# EFR32FG1V131F256GM48 register map
File version: 3.0.0
CPU: CM4 r0p1, little endian, MPU, FPU, 3 interrupt priority bits
Registers are 32-bit, read-write, reset 0x0 unless marked. A register's access mark holds for its fields unless they carry their own. Offsets are from the block's base; [hi:lo] are bit positions; {n}, {i} and the like mark numbered series; 'fields as' and 'values as' point back to an identical list.

## CRC — RF CRC engine
Base 0x40082000
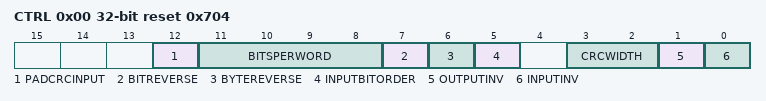
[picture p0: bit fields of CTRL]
0x00 CTRL reset 0x704
  [12] PADCRCINPUT, [11:8] BITSPERWORD, [7] BITREVERSE, [6] BYTEREVERSE, [5] INPUTBITORDER, [3:2] CRCWIDTH, [1] OUTPUTINV, [0] INPUTINV
0x04 STATUS ro
  [0] BUSY
0x08 CMD wo (reset mask 0x1)
  [5:0] INITIALIZE
0x0C INPUTDATA
  [15:0] INPUTDATA
0x10 INIT
0x14 DATA ro
0x18 POLY

## SYNTH — Frequency synthezicer
Base 0x40083000
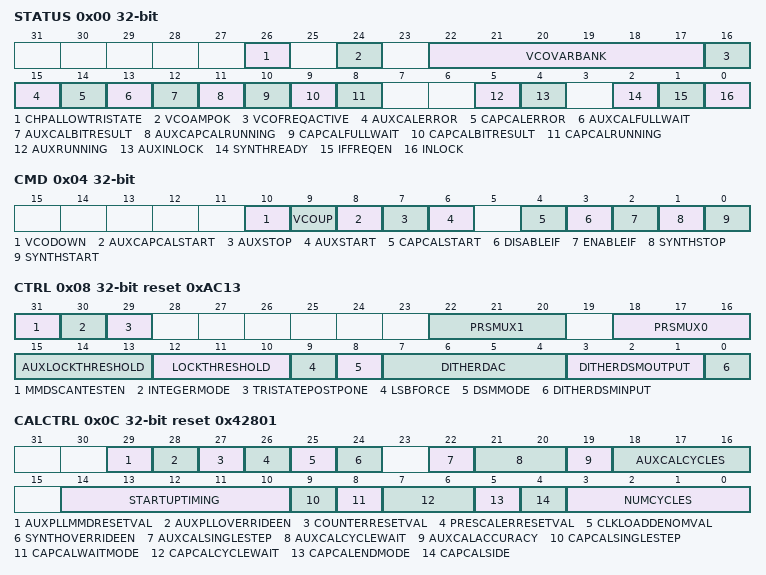
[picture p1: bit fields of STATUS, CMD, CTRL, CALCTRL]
0x00 STATUS ro
  [26] CHPALLOWTRISTATE, [24] VCOAMPOK, [22:17] VCOVARBANK, [16] VCOFREQACTIVE, [15] AUXCALERROR, [14] CAPCALERROR, [13] AUXCALFULLWAIT, [12] AUXCALBITRESULT, [11] AUXCAPCALRUNNING, [10] CAPCALFULLWAIT, [9] CAPCALBITRESULT, [8] CAPCALRUNNING, [5] AUXRUNNING, [4] AUXINLOCK, [2] SYNTHREADY, [1] IFFREQEN, [0] INLOCK
0x04 CMD wo
  [10] VCODOWN, [9] VCOUP, [8] AUXCAPCALSTART, [7] AUXSTOP, [6] AUXSTART, [4] CAPCALSTART, [3] DISABLEIF, [2] ENABLEIF, [1] SYNTHSTOP, [0] SYNTHSTART
0x08 CTRL reset 0xAC13
  [31] MMDSCANTESTEN, [30] INTEGERMODE, [29] TRISTATEPOSTPONE, [22:20] PRSMUX1, [18:16] PRSMUX0, [15:13] AUXLOCKTHRESHOLD, [12:10] LOCKTHRESHOLD, [9] LSBFORCE, [8] DSMMODE, [7:4] DITHERDAC, [3:1] DITHERDSMOUTPUT, [0] DITHERDSMINPUT
0x0C CALCTRL reset 0x42801
  [29] AUXPLLMMDRESETVAL, [28] AUXPLLOVERRIDEEN, [27] COUNTERRESETVAL, [26] PRESCALERRESETVAL, [25] CLKLOADDENOMVAL, [24] SYNTHOVERRIDEEN, [22] AUXCALSINGLESTEP, [21:20] AUXCALCYCLEWAIT, [19] AUXCALACCURACY, [18:16] AUXCALCYCLES, [14:10] STARTUPTIMING, [9] CAPCALSINGLESTEP, [8] CAPCALWAITMODE, [7:6] CAPCALCYCLEWAIT, [5] CAPCALENDMODE, [4] CAPCALSIDE, [3:0] NUMCYCLES
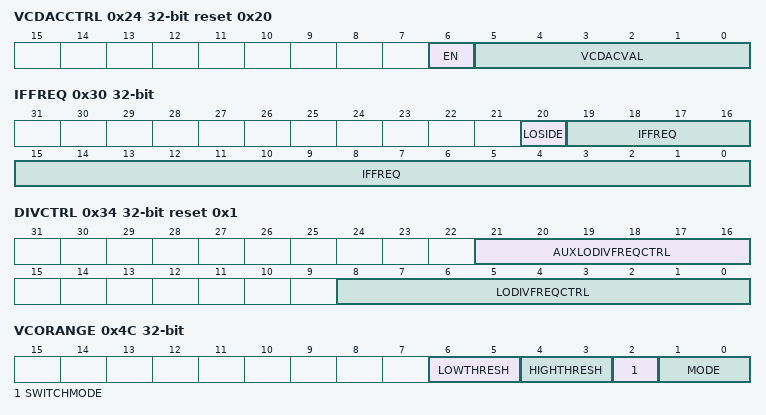
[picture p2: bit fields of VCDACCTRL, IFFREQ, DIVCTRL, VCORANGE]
0x24 VCDACCTRL reset 0x20
  [6] EN, [5:0] VCDACVAL
0x2C FREQ
  [27:0] FREQ
0x30 IFFREQ
  [20] LOSIDE, [19:0] IFFREQ
0x34 DIVCTRL reset 0x1
  [21:16] AUXLODIVFREQCTRL, [8:0] LODIVFREQCTRL
0x38 CHCTRL
  [5:0] CHNO
0x3C CHSP
  [17:0] CHSP
0x40 CALOFFSET
  [14:0] CALOFFSET
0x44 VCOTUNING reset 0x80
  [7:0] VCOTUNING
0x4C VCORANGE
  [6:5] LOWTHRESH, [4:3] HIGHTHRESH, [2] SWITCHMODE, [1:0] MODE
0x50 VCOGAIN reset 0x1F
  [5:0] VCOGAIN
0x54 AUXVCOTUNING
  [6:0] AUXVCOTUNING
0x58 AUXFREQ
  [6:0] MMDDENOM
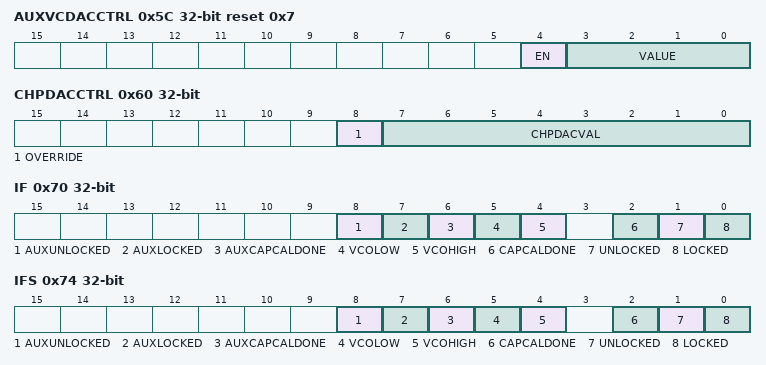
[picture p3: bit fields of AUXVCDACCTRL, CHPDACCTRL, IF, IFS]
0x5C AUXVCDACCTRL reset 0x7
  [4] EN, [3:0] VALUE
0x60 CHPDACCTRL
  [8] OVERRIDE, [7:0] CHPDACVAL
0x64 CAPCALCYCLECNT
  [9:0] CAPCALCYCLECNT
0x70 IF ro
  [8] AUXUNLOCKED, [7] AUXLOCKED, [6] AUXCAPCALDONE, [5] VCOLOW, [4] VCOHIGH, [2] CAPCALDONE, [1] UNLOCKED, [0] LOCKED
0x74 IFS wo
  fields as IF
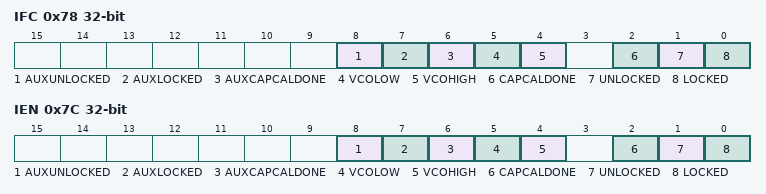
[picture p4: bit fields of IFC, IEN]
0x78 IFC wo
  fields as IF
0x7C IEN
  fields as IF

## SYNTH_CLR — Frequency synthezicer
Base 0x44083000
Same registers: SYNTH_SET 0x46083000
Registers as SYNTH; these are added or differ:
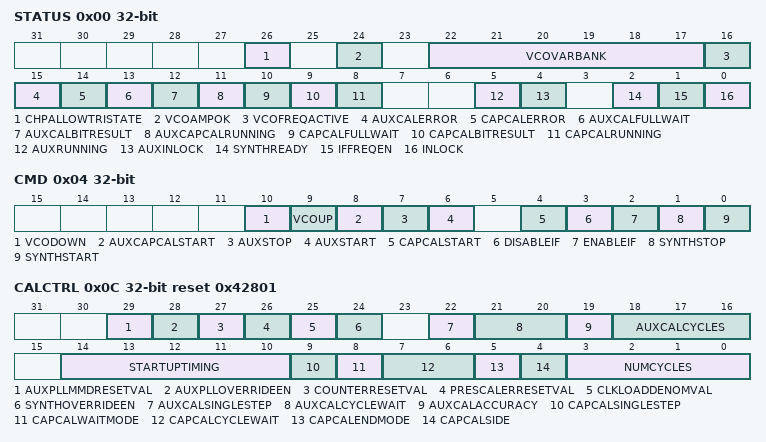
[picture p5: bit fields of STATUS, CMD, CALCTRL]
0x00 STATUS ro
  fields as SYNTH.STATUS
0x04 CMD wo
  [10] VCODOWN, [9] VCOUP, [8] AUXCAPCALSTART, [7] AUXSTOP, [6] AUXSTART, [4] CAPCALSTART, [3] DISABLEIF, [2] ENABLEIF, [1] SYNTHSTOP, [0] SYNTHSTART
0x0C CALCTRL reset 0x42801
  fields as SYNTH.CALCTRL

## RFSENSE
Base 0x40088000
Same registers: RFSENSE_CLR 0x44088000, RFSENSE_SET 0x46088000
0x00 CTRL
0x04 PERIODSEL
0x08 CNT
0x10 EM4WUEN
0x14 CALIB
0x18 IF ro
0x1C IFS wo
0x20 IFC wo
0x24 IEN

## SEQ — Sequencer
Base 0x21000F00
0x00 REG000
  [31:0] ADDRESS
0x04 REG004
  [31:0] ADDRESS
0x08 REG008
  [31:0] ADDRESS
{0xC+0x10*i} REG{i:02}C (i=0..9)
  [31:0] ADDRESS
0x10 REG010
  [31:0] ADDRESS
0x14 REG014
  [31:0] ADDRESS
0x18 REG018
  [31:0] ADDRESS
0x20 REG020
  [31:0] ADDRESS
0x24 REG024
  [31:0] ADDRESS
0x28 REG028
  [31:0] ADDRESS
0x30 REG030
  [31:0] ADDRESS
0x34 REG034
  [31:0] ADDRESS
0x38 REG038
  [31:0] ADDRESS
0x40 REG040
  [31:0] ADDRESS
0x44 REG044
  [31:0] ADDRESS
0x48 REG048
  [31:0] ADDRESS
0x50 REG050
  [31:0] ADDRESS
0x54 REG054
  [31:0] ADDRESS
0x58 REG058
  [31:0] ADDRESS
0x60 REG060
  [31:0] ADDRESS
0x64 REG064
  [31:0] ADDRESS
0x68 REG068
  [31:0] ADDRESS
0x70 REG070
  [31:0] ADDRESS
0x74 REG074
  [31:0] ADDRESS
0x78 REG078
  [31:0] ADDRESS
0x80 REG080
  [31:0] ADDRESS
0x84 REG084
  [31:0] ADDRESS
0x88 REG088
  [31:0] ADDRESS
0x90 REG090
  [31:0] ADDRESS
0x94 REG094
  [31:0] ADDRESS
0x98 REG098
  [31:0] ADDRESS
0xA0 REG0A0
  [31:0] ADDRESS
0xA4 REG0A4
  [31:0] ADDRESS
0xA8 REG0A8
  [31:0] ADDRESS
0xAC REG0AC
  [31:0] ADDRESS
0xB0 REG0B0
  [31:0] ADDRESS
0xB4 REG0B4
  [31:0] ADDRESS
0xB8 REG0B8
  [31:0] ADDRESS
0xBC REG0BC
  [31:0] ADDRESS
0xC0 REG0C0
  [31:0] ADDRESS
0xC4 REG0C4
  [31:0] ADDRESS
0xC8 REG0C8
  [31:0] ADDRESS
0xCC REG0CC
  [31:0] ADDRESS
0xD0 REG0D0
  [31:0] ADDRESS
0xD4 REG0D4
  [31:0] ADDRESS
0xD8 REG0D8
  [31:0] ADDRESS
0xDC REG0DC
  [31:0] ADDRESS
0xE0 REG0E0
  [31:0] ADDRESS
0xE4 REG0E4
  [31:0] ADDRESS
0xE8 REG0E8
  [31:0] ADDRESS
0xEC DYNAMIC_CHPWR_TABLE
  [31:0] ADDRESS
0xF0 PHYINFO
  [31:0] ADDRESS
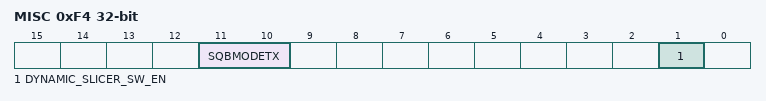
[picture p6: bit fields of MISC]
0xF4 MISC
  [11:10] SQBMODETX, [1] DYNAMIC_SLICER_SW_EN
0xF8 SYNTHLPFCTRLRX
0xFC SYNTHLPFCTRLTX

## CRC_CLR — RF CRC engine
Base 0x44082000
Same registers: CRC_SET 0x46082000
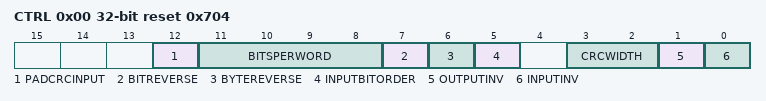
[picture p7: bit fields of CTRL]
0x00 CTRL reset 0x704
  [12] PADCRCINPUT, [11:8] BITSPERWORD, [7] BITREVERSE, [6] BYTEREVERSE, [5] INPUTBITORDER, [3:2] CRCWIDTH, [1] OUTPUTINV, [0] INPUTINV
0x04 STATUS ro
  [0] BUSY
0x08 CMD wo (reset mask 0x1)
  [5:0] INITIALIZE
0x0C INPUTDATA
  [15:0] INPUTDATA
0x10 INIT
0x14 DATA ro
0x18 POLY

## BUFC — Buffer controller
Base 0x40081000
Same registers: BUFC_CLR 0x44081000, BUFC_SET 0x46081000
{0x0+0x30*i} BUF{i}_CTRL (i=0..3)
  [2:0] SIZE — Buffer Size
    0=Sets Buffer size to 64 bytes; 1=Sets Buffer size to 128 bytes; 2=Sets Buffer size to 256 bytes; 3=Sets Buffer size to 512 bytes; 4=Sets Buffer size to 1024 bytes; 5=Sets Buffer size to 2048 bytes; 6=Sets Buffer size to 4096 bytes
{0x4+0x30*i} BUF{i}_ADDR (i=0..3)
  [23:0] ADDR — Buffer Address
{0x8+0x30*i} BUF{i}_WRITEOFFSET (i=0..3)
  [12:0] WRITEOFFSET
{0xC+0x30*i} BUF{i}_READOFFSET (i=0..3)
  [12:0] READOFFSET
{0x10+0x30*i} BUF{i}_WRITESTART (i=0..3)
{0x14+0x30*i} BUF{i}_READDATA ro (i=0..3)
  [7:0] READDATA — Buffer Read Data
{0x18+0x30*i} BUF{i}_WRITEDATA wo (i=0..3)
  [7:0] WRITEDATA — Buffer Write Data
{0x1C+0x30*i} BUF{i}_XWRITE wo (i=0..3)
  [7:0] XORWRITEDATA — Buffer XOR Write Data
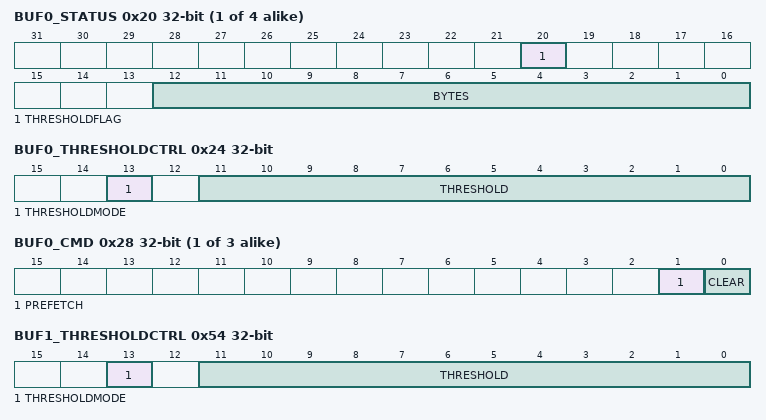
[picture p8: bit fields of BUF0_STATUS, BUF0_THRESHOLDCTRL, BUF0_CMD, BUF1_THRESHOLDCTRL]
{0x20+0x30*i} BUF{i}_STATUS ro (i=0..3)
  [20] THRESHOLDFLAG — Buffer Threshold Flag
  [12:0] BYTES — Number of Bytes in the Buffer
0x24 BUF0_THRESHOLDCTRL
  [13] THRESHOLDMODE — Buffer Threshold Mode
    0=LARGER (THRESHOLDIF will be set if BYTES is larger than THRESHOLD); 1=LESSOREQUAL (THRESHOLDIF will be set if BYTES is less than or equal to THRESHOLD)
  [11:0] THRESHOLD — Buffer Threshold Value
{0x28+0x30*i} BUF{i}_CMD wo (i=0..2)
  [1] PREFETCH
  [0] CLEAR — Buffer Clear
0x54 BUF1_THRESHOLDCTRL
  fields as BUF0_THRESHOLDCTRL
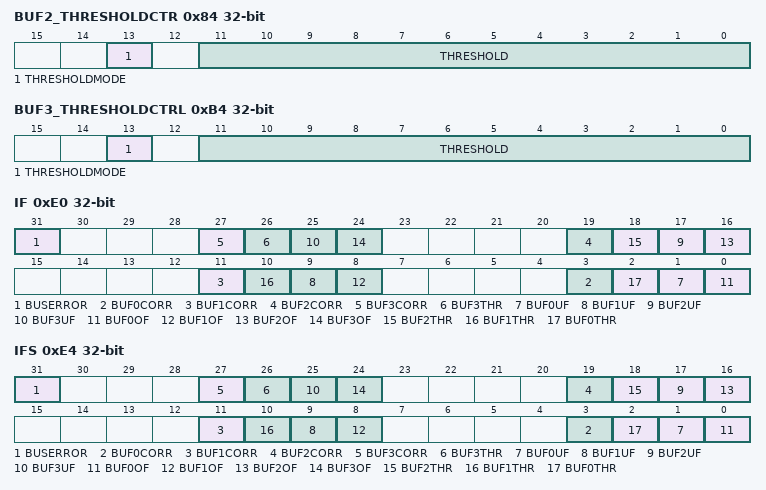
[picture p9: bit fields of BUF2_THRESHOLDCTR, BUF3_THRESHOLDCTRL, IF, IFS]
0x84 BUF2_THRESHOLDCTR
  fields as BUF0_THRESHOLDCTRL
0xB4 BUF3_THRESHOLDCTRL
  fields as BUF0_THRESHOLDCTRL
0xB8 BUF3_CMD write-only
						write-only
  [1] PREFETCH wo
  [0] CLEAR wo — Buffer Clear
0xE0 IF
  [31] BUSERROR
  [8n+3] BUF{n}CORR (n=0..3) — Buffer {n} Corrupt
  [26] BUF3THR — Buffer 3 Threshold Event
  [8n+1] BUF{n}UF (n=0..3) — Buffer {n} Underflow
  [8n] BUF{n}OF (n=0..3) — Buffer {n} Overflow
  [18] BUF2THR — Buffer 2 Threshold Event
  [10] BUF1THR — Buffer 2 Threshold Event
  [2] BUF0THR — Buffer 0 Threshold Event
0xE4 IFS
  fields as IF
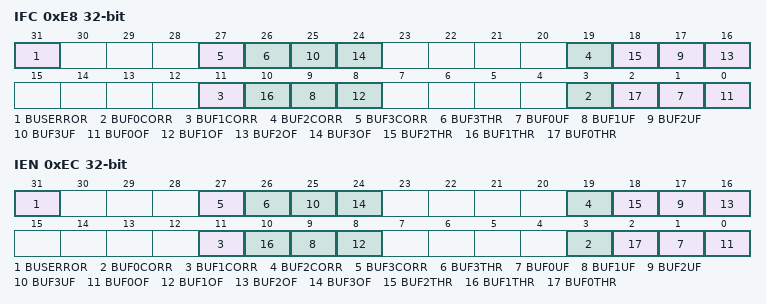
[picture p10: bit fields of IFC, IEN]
0xE8 IFC
  fields as IF
0xEC IEN
  fields as IF
